# B6x register map
Vendor: XiaoMan; Series: B6 SOC; File version: 20260307
CPU: CM0+ r0p0, little endian, no MPU, no FPU, 2 interrupt priority bits
Registers are 32-bit, read-write, reset 0x0 unless marked. A register's access mark holds for its fields unless they carry their own. Offsets are from the block's base; [hi:lo] are bit positions; {n}, {i} and the like mark numbered series.

## RF — Radio Freq
Base 0x4002C000
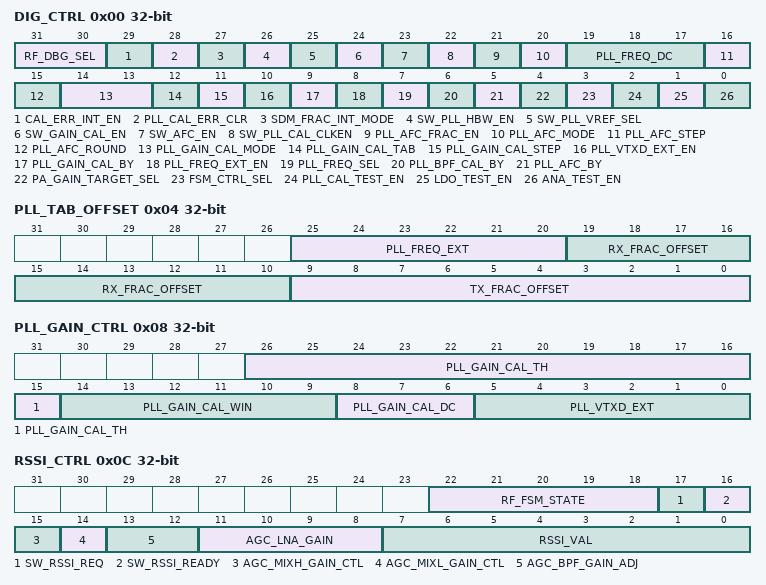
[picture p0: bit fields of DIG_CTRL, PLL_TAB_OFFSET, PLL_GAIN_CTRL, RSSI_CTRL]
0x00 DIG_CTRL
  [31:30] RF_DBG_SEL — 1---tx, 2---rx
  [29] CAL_ERR_INT_EN
  [28] PLL_CAL_ERR_CLR
  [27] SDM_FRAC_INT_MODE — SDM_FRAC_INT_MODE Enable or Disable
  [26] SW_PLL_HBW_EN — SW_PLL_HBW_EN Enable or Disable
    1=Enable (software set PLL is in HBW_EN as 1); 0=Disable (HBW_EN is driven by pll_cal logic)
  [25] SW_PLL_VREF_SEL — SW_PLL_VREF_SEL Enable or Disable
    1=Enable (use to control DAC_VREF_SEL when pll_gain_cal_step is 1 or used when pll_cal_test_en is 1); 0=Disable (rfdig FSM control)
  [24] SW_GAIN_CAL_EN — SW_GAIN_CAL_EN Enable or Disable
    1=Enable (PLL GAIN Calibration start work, only effect when pll_gain_cal_by is 1); 0=Disable (rfdig FSM control)
  [23] SW_AFC_EN — SW_AFC_EN Enable or Disable
    1=Enable (PLL AFC Calibration start work, only effect when pll_afc_by is 1); 0=Disable (rfdig FSM control)
  [22] SW_PLL_CAL_CLKEN — SW_PLL_CAL_CLKEN Enable or Disable
    1=enable PLL AFC and GAIN CAL clock by MCU, set as 1 when pll_afc_by or pll_gain_cal_by is 1; 0=Disable (rfdig FSM control)
  [21] PLL_AFC_FRAC_EN — PLL_AFC_FRAC_EN Enable or Disable
    1=Enable (use PLL_FRAC[23]); 0=Disable (rfdig FSM control)
  [20] PLL_AFC_MODE — PLL_AFC_MODE Enable or Disable
    1=Enable (don't set hbw_en as 1 when AFC is done, makesure pll_gain_cal_by is 0); 0=Disable (set hbw_en as 1 when AFC is done)
  [19:17] PLL_FREQ_DC — DC offset used for AFC calib done
  [16] PLL_AFC_STEP — PLL_AFC_STEP Enable or Disable, only effect when pll_afc_by is 1
    1=Enable (MCU step by step debug PLL AFC); 0=Disable (rfdig FSM step debug PLL AFC)
  [15] PLL_AFC_ROUND — PLL_AFC_ROUND Enable or Disable
    1=Enable (rfdig FSM bypass AFC calib, AFC calib can be start by software); 0=Disable (floor result)
  [14:13] PLL_GAIN_CAL_MODE — active when pll_gain_cal_by is 1 and pll_vtxd_ext_en is 0 and pll_gain_cal_step is 0
  [12] PLL_GAIN_CAL_TAB — active when pll_gain_cal_by is 1 and pll_vtxd_ext_en is 0 and pll_gain_cal_step is 0
    1=Enable (PLL_DAC_ADJ[4:0] is driven by lookup table); 0=Disable (PLL_DAC_ADJ[4:0] is driven by lookup table)
  [11] PLL_GAIN_CAL_STEP — PLL_GAIN_CAL_STEP Enable or Disable
    1=Enable (MCU step by step debug PLL GAIN CAL, only effect when pll_gain_cal_by is 1); 0=Disable (rfdig FSM PLL GAIN CAL)
  [10] PLL_VTXD_EXT_EN — PLL_VTXD_EXT_EN Enable or Disable
    1=Enable (PLL_DAC_ADJ[4:0] is driven by PLL_VTXD_EXT); 0=Disable (PLL_DAC_ADJ[4:0] is driven by GAIN Calib logic)
  [9] PLL_GAIN_CAL_BY — PLL_GAIN_CAL_BY Enable or Disable
    1=Enable (rfdig FSM bypass PLL GAIN calib, PLL GAIN calib can be start by software); 0=Disable (rfdig FSM start PLL GAIN calib)
  [8] PLL_FREQ_EXT_EN — PLL_FREQ_EXT_EN Enable or Disable
    1=Enable (PLL_FREQ_ADJ[5:0] is driven by PLL_FREQ_EXT); 0=Disable (PLL_FREQ_ADJ[5:0] is driven by AFC Calib logic)
  [7] PLL_FREQ_SEL — PLL_FREQ_SEL Enable or Disable
    1=Enable (PLL frequency is controlled by reg sw_di_s and sw_frac); 0=Disable (PLL frequency is controlled by channel number)
  [6] PLL_BPF_CAL_BY — PLL_BPF_CAL_BY Enable or Disable
    1=Enable (rfdig FSM bypass AFC calib, AFC calib can be start by software); 0=Disable (rfdig FSM start BPF calib)
  [5] PLL_AFC_BY — PLL_AFC_BY Enable or Disable
    1=Enable (rfdig FSM bypass AFC calib, AFC calib can be start by software); 0=Disable (rfdig FSM start AFC calib)
  [4] PA_GAIN_TARGET_SEL — PA_GAIN_TARGET_SEL Enable or Disable
    1=Enable (the pa_gain_target is from sw_pa_gain_target); 0=Disable (the pa_gain_target is from BB)
  [3] FSM_CTRL_SEL — FSM_CTRL_SEL Enable or Disable
    1=Enable (RF Dig FSM input signal is from rf_reg); 0=Disable (RF Dig FSM input signal is from BB)
  [2] PLL_CAL_TEST_EN — PLL_CAL_TEST_EN Enable or Disable
    1=Enable (PLL AFC and GAIN CAL directed controlled by reg); 0=Disable (PLL AFC and GAIN CAL controlled by rf_pll_cal module)
  [1] LDO_TEST_EN — LDO_TEST_EN Enable or Disable
    1=Enable (analog block power is controlled by reg); 0=Disable (analog block power is controlled by RF Dig FSM)
  [0] ANA_TEST_EN — ANA_TEST_EN Enable or Disable
    1=Enable (RF ANALOG digital input is controlled by reg); 0=Disable (RF ANALOG digital input is controlled by rfdig_gsm)
0x04 PLL_TAB_OFFSET
  [25:20] PLL_FREQ_EXT — used when pll_freq_ext_en or pll_afc_step is 1
  [19:10] RX_FRAC_OFFSET — signed data, unit : 1MHz/1024, near as 1KHz, arrange: -512KHz ~ 511 KHz
  [9:0] TX_FRAC_OFFSET — signed data, unit : 1MHz/1024, near as 1KHz, arrange: -512KHz ~ 511 KHz
0x08 PLL_GAIN_CTRL
  [26:15] PLL_GAIN_CAL_TH — df1 : 250K * 80 = 40M, pll_gain_cal_th : 40 * (GAIN CAL step window)
  [14:9] PLL_GAIN_CAL_WIN — PLL GAIN CAL step window, step window time : (pll_gain_cal_win + 1) us
  [8:6] PLL_GAIN_CAL_DC — DC offset used for GAIN CAL calib done, signed data: -4 ~ 3
  [5:0] PLL_VTXD_EXT — used when pll_vtxd_ext_en or pll_gain_cal_step is 1
0x0C RSSI_CTRL
  [22:18] RF_FSM_STATE, [17] SW_RSSI_REQ, [16] SW_RSSI_READY, [15] AGC_MIXH_GAIN_CTL, [14] AGC_MIXL_GAIN_CTL, [13:12] AGC_BPF_GAIN_ADJ, [11:8] AGC_LNA_GAIN, [7:0] RSSI_VAL
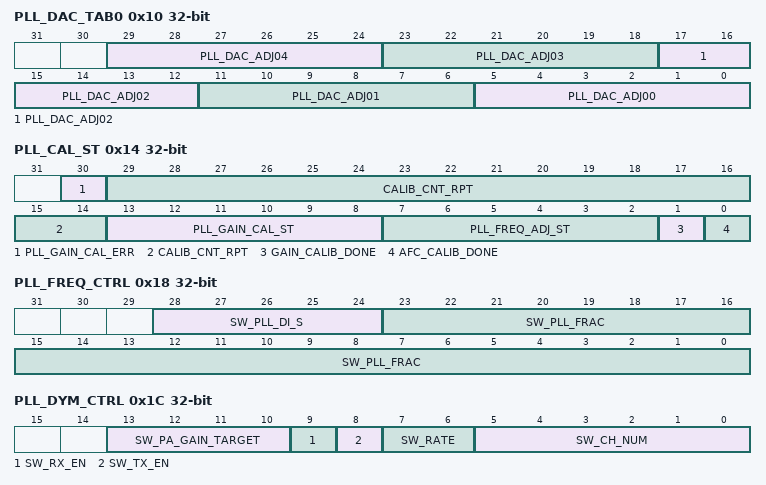
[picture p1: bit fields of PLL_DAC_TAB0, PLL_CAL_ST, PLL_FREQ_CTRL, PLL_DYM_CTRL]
0x10 PLL_DAC_TAB0
  [6n+5:6n] PLL_DAC_ADJ{n:02} (n=0..4)
0x14 PLL_CAL_ST
  [30] PLL_GAIN_CAL_ERR, [29:14] CALIB_CNT_RPT, [13:8] PLL_GAIN_CAL_ST, [7:2] PLL_FREQ_ADJ_ST, [1] GAIN_CALIB_DONE, [0] AFC_CALIB_DONE
0x18 PLL_FREQ_CTRL
  [28:24] SW_PLL_DI_S, [23:0] SW_PLL_FRAC
0x1C PLL_DYM_CTRL
  [13:10] SW_PA_GAIN_TARGET — when ana_test is 1, PA_GAIN is driven by pa_gain_target, else PA_GAIN is driven by RF Dig FSM, and ramp up to pa_gain_target
  [9] SW_RX_EN — only used when FSM_CTRL_SEL is 1
    1=Enable (Rx Enable); 0=Disable (Rx Disable)
  [8] SW_TX_EN — only used when FSM_CTRL_SEL is 1
    1=Enable (Tx Enable); 0=Disable (Tx Disable)
  [7:6] SW_RATE — only used when FSM_CTRL_SEL is 1
    0=1M (1Mbps); 1=2M (2Mbps)
  [5:0] SW_CH_NUM — only used when FSM_CTRL_SEL is 1
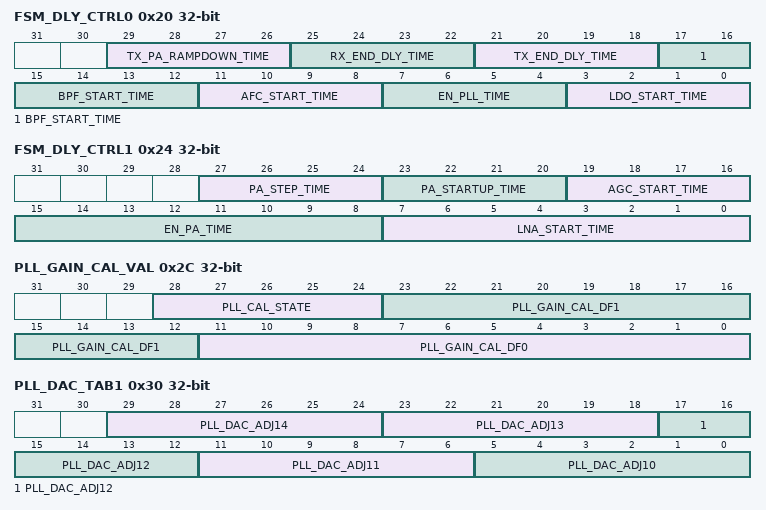
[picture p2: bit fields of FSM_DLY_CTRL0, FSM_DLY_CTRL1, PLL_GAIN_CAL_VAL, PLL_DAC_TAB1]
0x20 FSM_DLY_CTRL0
  [29:26] TX_PA_RAMPDOWN_TIME — delay (tx_pa_rampdown_time+1) us to start PA RAMPDOWN after neg of modem_tx_en
  [25:22] RX_END_DLY_TIME — delay (rx_end_dly_time + 1) us from neg of bb_rx_en to neg modem_rx_en
  [21:18] TX_END_DLY_TIME — delay (tx_end_dly_time + 1) us from neg of bb_tx_en to neg modem_tx_en
  [17:12] BPF_START_TIME — delay bpf_start_tim us to enable BPF CAL after pll enable
  [11:8] AFC_START_TIME — delay (afc_start_time +1) us to enable AFC after pll enable, 2~10 us, default is 3us
  [7:4] EN_PLL_TIME — after LDO stable, delay (en_pll_time + 1) us, then enable PLL; unit : us, 2~10 us, default is 3us
  [3:0] LDO_START_TIME — wait RF LDO stable time (ldo_start_time + 1) us , and then select PLL_RTX_SEL value, unit is us, 2~10 us, default is 3us
0x24 FSM_DLY_CTRL1
  [27:24] PA_STEP_TIME — PA GAIN step time, unit 0.5us, step time : 0.5* ( pa_step_time + 1 ) us, 0.5 ~ 8us, 0 is forbidden
  [23:20] PA_STARTUP_TIME — start PA rampup time after PA GAIN enable
  [19:16] AGC_START_TIME — delay (agc_start_time +1) us to enable AGC after enable LNA and MIXER
  [15:8] EN_PA_TIME — delay (enpa_time +1) us to enable PA_GAIN after pll enable, make sure en_pa_time is larger than afc_start_time
  [7:0] LNA_START_TIME — delay (lna_start_time +1) us to enable, LNA, MIX, BPF, LMT, RSSI, after pll enable
0x28 PLL_CAL_DAC_STEP
0x2C PLL_GAIN_CAL_VAL
  [28:24] PLL_CAL_STATE, [23:12] PLL_GAIN_CAL_DF1, [11:0] PLL_GAIN_CAL_DF0
0x30 PLL_DAC_TAB1
  [29:24] PLL_DAC_ADJ14 — PLL_DAC_ADJ04
  [6n-55:6n-60] PLL_DAC_ADJ{n} (n=10..13)
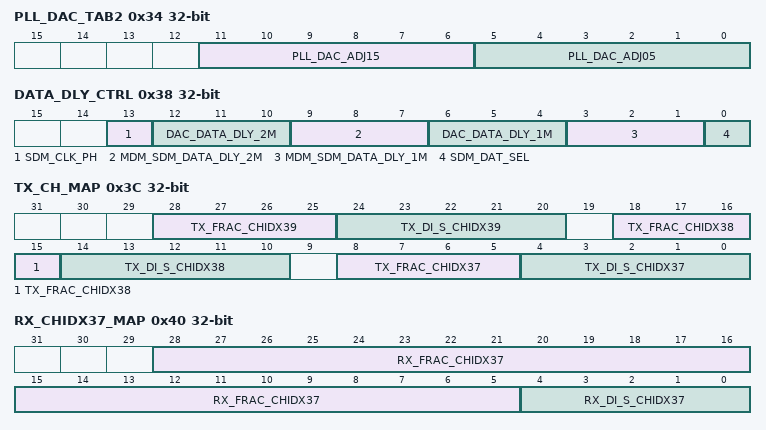
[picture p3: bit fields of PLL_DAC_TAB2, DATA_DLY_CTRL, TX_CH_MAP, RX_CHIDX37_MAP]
0x34 PLL_DAC_TAB2
  [11:6] PLL_DAC_ADJ15, [5:0] PLL_DAC_ADJ05
0x38 DATA_DLY_CTRL
  [13] SDM_CLK_PH — 1: inverter the BAKIN_PFD clock for SDM
  [12:10] DAC_DATA_DLY_2M
  [9:7] MDM_SDM_DATA_DLY_2M
  [6:4] DAC_DATA_DLY_1M
  [3:1] MDM_SDM_DATA_DLY_1M
  [0] SDM_DAT_SEL — 0: SDM data from rf_ana, 1: SDM data from mdm
0x3C TX_CH_MAP
  [28:25] TX_FRAC_CHIDX39 — high 4bits of the tx_frac[23:0], low 20bits is 0
  [24:20] TX_DI_S_CHIDX39
  [18:15] TX_FRAC_CHIDX38 — high 4bits of the tx_frac[23:0], low 20bits is 0
  [14:10] TX_DI_S_CHIDX38
  [8:5] TX_FRAC_CHIDX37 — high 4bits of the tx_frac[23:0], low 20bits is 0
  [4:0] TX_DI_S_CHIDX37
0x40 RX_CHIDX37_MAP
  [28:5] RX_FRAC_CHIDX37, [4:0] RX_DI_S_CHIDX37
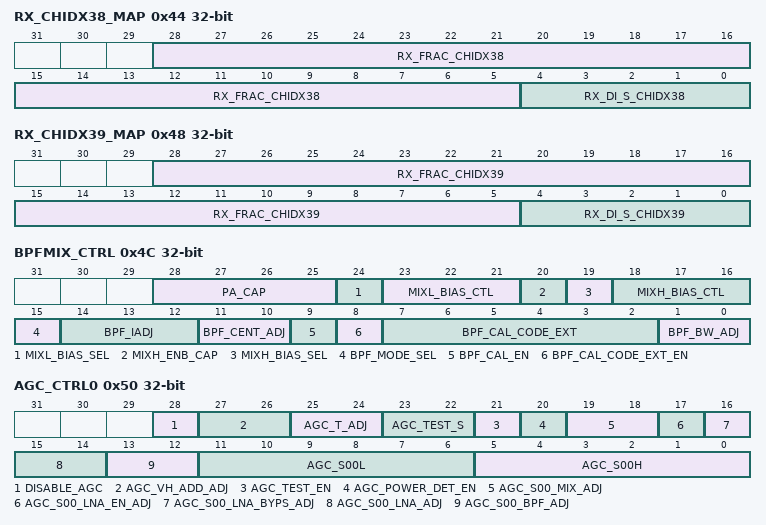
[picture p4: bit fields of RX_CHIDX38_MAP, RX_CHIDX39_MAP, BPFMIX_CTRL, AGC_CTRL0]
0x44 RX_CHIDX38_MAP
  [28:5] RX_FRAC_CHIDX38, [4:0] RX_DI_S_CHIDX38
0x48 RX_CHIDX39_MAP
  [28:5] RX_FRAC_CHIDX39, [4:0] RX_DI_S_CHIDX39
0x4C BPFMIX_CTRL
  [28:25] PA_CAP
  [24] MIXL_BIAS_SEL
  [23:21] MIXL_BIAS_CTL
  [20] MIXH_ENB_CAP
  [19] MIXH_BIAS_SEL
  [18:16] MIXH_BIAS_CTL
  [15] BPF_MODE_SEL
  [14:12] BPF_IADJ
  [11:10] BPF_CENT_ADJ
  [9] BPF_CAL_EN — only used when pll_bpf_cal_by is 1
    1=Enable (BPF_CAL_EN Enable); 0=Disable (BPF_CAL_EN Disable)
  [8] BPF_CAL_CODE_EXT_EN
    1=Enable (BPF_CAL_CODE_EXT_EN Enable); 0=Disable (BPF_CAL_CODE_EXT_EN Disable)
  [7:2] BPF_CAL_CODE_EXT
  [1:0] BPF_BW_ADJ
0x50 AGC_CTRL0
  [28] DISABLE_AGC, [27:26] AGC_VH_ADD_ADJ, [25:24] AGC_T_ADJ, [23:22] AGC_TEST_S, [21] AGC_TEST_EN, [20] AGC_POWER_DET_EN, [19:18] AGC_S00_MIX_ADJ, [17] AGC_S00_LNA_EN_ADJ, [16] AGC_S00_LNA_BYPS_ADJ, [15:14] AGC_S00_LNA_ADJ, [13:12] AGC_S00_BPF_ADJ, [11:6] AGC_S00L, [5:0] AGC_S00H
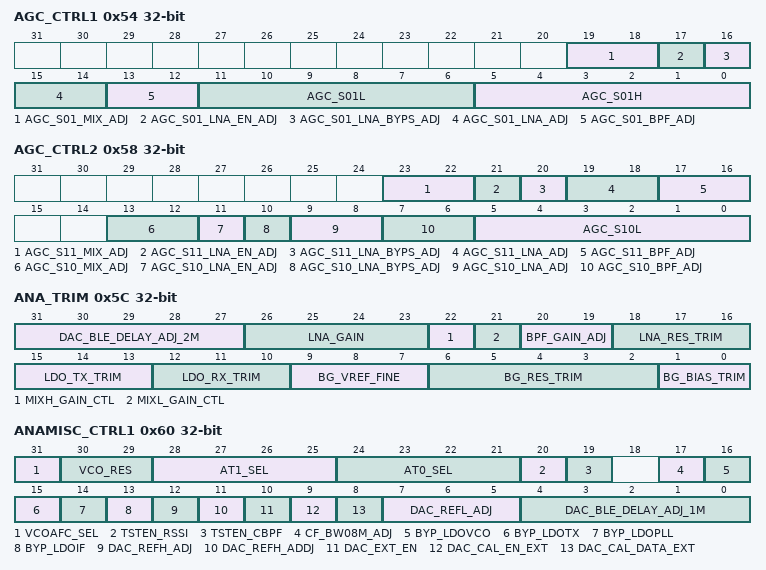
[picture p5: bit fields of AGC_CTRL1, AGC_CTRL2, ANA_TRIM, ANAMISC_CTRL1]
0x54 AGC_CTRL1
  [19:18] AGC_S01_MIX_ADJ, [17] AGC_S01_LNA_EN_ADJ, [16] AGC_S01_LNA_BYPS_ADJ, [15:14] AGC_S01_LNA_ADJ, [13:12] AGC_S01_BPF_ADJ, [11:6] AGC_S01L, [5:0] AGC_S01H
0x58 AGC_CTRL2
  [23:22] AGC_S11_MIX_ADJ, [21] AGC_S11_LNA_EN_ADJ, [20] AGC_S11_LNA_BYPS_ADJ, [19:18] AGC_S11_LNA_ADJ, [17:16] AGC_S11_BPF_ADJ, [13:12] AGC_S10_MIX_ADJ, [11] AGC_S10_LNA_EN_ADJ, [10] AGC_S10_LNA_BYPS_ADJ, [9:8] AGC_S10_LNA_ADJ, [7:6] AGC_S10_BPF_ADJ, [5:0] AGC_S10L
0x5C ANA_TRIM
  [31:27] DAC_BLE_DELAY_ADJ_2M, [26:23] LNA_GAIN, [22] MIXH_GAIN_CTL, [21] MIXL_GAIN_CTL, [20:19] BPF_GAIN_ADJ, [18:16] LNA_RES_TRIM, [15:13] LDO_TX_TRIM, [12:10] LDO_RX_TRIM, [9:7] BG_VREF_FINE, [6:2] BG_RES_TRIM, [1:0] BG_BIAS_TRIM
0x60 ANAMISC_CTRL1
  [31] VCOAFC_SEL
  [30:29] VCO_RES
  [28:25] AT1_SEL
  [24:21] AT0_SEL
  [20] TSTEN_RSSI
  [19] TSTEN_CBPF
  [17] CF_BW08M_ADJ
  [16] BYP_LDOVCO
  [15] BYP_LDOTX
  [14] BYP_LDOPLL
  [13] BYP_LDOIF
  [12] DAC_REFH_ADJ
  [11] DAC_REFH_ADDJ
  [10] DAC_EXT_EN
  [9] DAC_CAL_EN_EXT
  [8] DAC_CAL_DATA_EXT — XOSCDAC_CAL_DATA_EXT16M_EN_ST
  [7:5] DAC_REFL_ADJ
  [4:0] DAC_BLE_DELAY_ADJ_1M
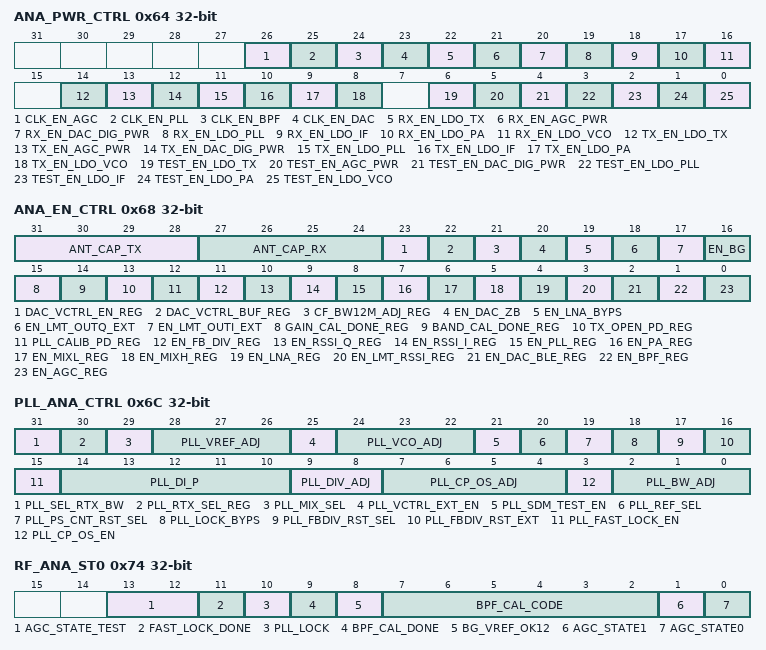
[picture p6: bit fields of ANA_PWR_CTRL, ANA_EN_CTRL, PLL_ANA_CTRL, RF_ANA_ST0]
0x64 ANA_PWR_CTRL
  [26] CLK_EN_AGC
  [25] CLK_EN_PLL
  [24] CLK_EN_BPF
  [23] CLK_EN_DAC
  [22] RX_EN_LDO_TX — used when RF is controlled by RF Dig FSM and in RX mode
  [21] RX_EN_AGC_PWR — used when RF is controlled by RF Dig FSM and in RX mode
  [20] RX_EN_DAC_DIG_PWR — used when RF is controlled by RF Dig FSM and in RX mode
  [19] RX_EN_LDO_PLL — used when RF is controlled by RF Dig FSM and in RX mode
  [18] RX_EN_LDO_IF — used when RF is controlled by RF Dig FSM and in RX mode
  [17] RX_EN_LDO_PA — used when RF is controlled by RF Dig FSM and in RX mode
  [16] RX_EN_LDO_VCO — used when RF is controlled by RF Dig FSM and in RX mode
  [14] TX_EN_LDO_TX — used when RF is controlled by RF Dig FSM and in TX mode
  [13] TX_EN_AGC_PWR — used when RF is controlled by RF Dig FSM and in TX mode
  [12] TX_EN_DAC_DIG_PWR — used when RF is controlled by RF Dig FSM and in TX mode
  [11] TX_EN_LDO_PLL — used when RF is controlled by RF Dig FSM and in TX mode
  [10] TX_EN_LDO_IF — used when RF is controlled by RF Dig FSM and in TX mode
  [9] TX_EN_LDO_PA — used when RF is controlled by RF Dig FSM and in TX mode
  [8] TX_EN_LDO_VCO — used when RF is controlled by RF Dig FSM and in TX mode
  [6] TEST_EN_LDO_TX — used when ldo_test_en is 1
  [5] TEST_EN_AGC_PWR — used when ldo_test_en is 1
  [4] TEST_EN_DAC_DIG_PWR — used when ldo_test_en is 1
  [3] TEST_EN_LDO_PLL — used when ldo_test_en is 1
  [2] TEST_EN_LDO_IF — used when ldo_test_en is 1
  [1] TEST_EN_LDO_PA — used when ldo_test_en is 1
  [0] TEST_EN_LDO_VCO — used when ldo_test_en is 1
0x68 ANA_EN_CTRL
  [31:28] ANT_CAP_TX
  [27:24] ANT_CAP_RX
  [23] DAC_VCTRL_EN_REG
  [22] DAC_VCTRL_BUF_REG
  [21] CF_BW12M_ADJ_REG — used when ana_test_en is 1
  [20] EN_DAC_ZB — direct control RF ANA
  [19] EN_LNA_BYPS — direct control RF ANA
  [18] EN_LMT_OUTQ_EXT — direct control RF ANA
  [17] EN_LMT_OUTI_EXT — direct control RF ANA
  [16] EN_BG — direct control RF ANA
  [15] GAIN_CAL_DONE_REG — used when pll_cal_test_en as 1
  [14] BAND_CAL_DONE_REG — used when pll_cal_test_en as 1
  [13] TX_OPEN_PD_REG — used when pll_cal_test_en as 1
  [12] PLL_CALIB_PD_REG — used when pll_cal_test_en as 1
  [11] EN_FB_DIV_REG — used when pll_cal_test_en as 1
  [10] EN_RSSI_Q_REG — when EN_XXX_REG is 0 , signal is controlled by RF Dig FSM, when EN_XXX_REG is 1, the signal to analog is 1
  [9] EN_RSSI_I_REG — when EN_XXX_REG is 0 , signal is controlled by RF Dig FSM, when EN_XXX_REG is 1, the signal to analog is 1
  [8] EN_PLL_REG — when EN_XXX_REG is 0 , signal is controlled by RF Dig FSM, when EN_XXX_REG is 1, the signal to analog is 1
  [7] EN_PA_REG — when EN_XXX_REG is 0 , signal is controlled by RF Dig FSM, when EN_XXX_REG is 1, the signal to analog is 1
  [6] EN_MIXL_REG — when EN_XXX_REG is 0 , signal is controlled by RF Dig FSM, when EN_XXX_REG is 1, the signal to analog is 1
  [5] EN_MIXH_REG — when EN_XXX_REG is 0 , signal is controlled by RF Dig FSM, when EN_XXX_REG is 1, the signal to analog is 1
  [4] EN_LNA_REG — when EN_XXX_REG is 0 , signal is controlled by RF Dig FSM, when EN_XXX_REG is 1, the signal to analog is 1
  [3] EN_LMT_RSSI_REG — when EN_XXX_REG is 0 , signal is controlled by RF Dig FSM, when EN_XXX_REG is 1, the signal to analog is 1
  [2] EN_DAC_BLE_REG — when EN_XXX_REG is 0 , signal is controlled by RF Dig FSM, when EN_XXX_REG is 1, the signal to analog is 1
  [1] EN_BPF_REG — when EN_XXX_REG is 0 , signal is controlled by RF Dig FSM, when EN_XXX_REG is 1, the signal to analog is 1
  [0] EN_AGC_REG — when EN_XXX_REG is 0 , signal is controlled by RF Dig FSM, when EN_XXX_REG is 1, the signal to analog is 1
0x6C PLL_ANA_CTRL
  [31] PLL_SEL_RTX_BW — direct to RF Analog block
  [30] PLL_RTX_SEL_REG — used when ana_test_en is 1
  [29] PLL_MIX_SEL — 0: +2M IF for RX, 1: -2M IF for RX to RF Analog block
  [28:26] PLL_VREF_ADJ
  [25] PLL_VCTRL_EXT_EN
  [24:22] PLL_VCO_ADJ
  [21] PLL_SDM_TEST_EN
  [20] PLL_REF_SEL
  [19] PLL_PS_CNT_RST_SEL
  [18] PLL_LOCK_BYPS
  [17] PLL_FBDIV_RST_SEL
  [16] PLL_FBDIV_RST_EXT
  [15] PLL_FAST_LOCK_EN
  [14:10] PLL_DI_P
  [9:8] PLL_DIV_ADJ
  [7:4] PLL_CP_OS_ADJ
  [3] PLL_CP_OS_EN
  [2:0] PLL_BW_ADJ
0x70 RF_RSV
0x74 RF_ANA_ST0
  [13:12] AGC_STATE_TEST, [11] FAST_LOCK_DONE, [10] PLL_LOCK, [9] BPF_CAL_DONE, [8] BG_VREF_OK12, [7:2] BPF_CAL_CODE, [1] AGC_STATE1, [0] AGC_STATE0
